# B6x register map
Vendor: XiaoMan; Series: B6 SOC; File version: 20260307
Register cmsis file for DragonC parts
CPU: CM0+ r0p0, little endian, no MPU, no FPU, 2 interrupt priority bits
Registers are 32-bit, read-write, reset 0x0 unless marked. A register's access mark holds for its fields unless they carry their own. Offsets are from the block's base; lines under a group give offsets from that group; [hi:lo] are bit positions; {n}, {i} and the like mark numbered series; 'fields as' and 'values as' point back to an identical list; <NAME> marks a mode.

## Memory map
0x19000000 CACHE size 0x1C
0x40000000 RCC size 0x48 — Reset and Clock Control
0x40001000 SYSCFG size 0x48 — System Configuration
0x40002000 CSC size 0x18C
0x40004000 SPIM size 0x1C — SPI Master
0x40005000 SPIS size 0x14 — SPI Slave
0x40006000 FSHC size 0x60 — Flash Controller
0x40007000 ADC size 0x30
0x40009000 Modem size 0x3C — Modem Freq
0x40010000 GPIO size 0x34
0x40020000 BTMR size 0x5C — basic timer
0x40021000 CTMR size 0x5C — General Purpose Timer
0x40022000 ATMR size 0x5C — Advanced Timer
0x40023000 UART1 size 0x3C
0x40024000 UART2 size 0x3C
0x40026000 DMA size 0xE4C
0x40027000 DMACHCFG size 0x108
0x40028000 EXTI size 0xE30 — External interrupt
0x40029000 I2C size 0x40 — IIC
0x4002A000 IWDT size 0x104 — Independent WatchDog Timer
0x4002C000 RF size 0x78 — Radio Freq
0x40030000 AON size 0x2C — Always On Domain
0x40031000 APBMISC size 0x88

## Interrupts
0 EXTI
1 IWDT
3 DMACHCFG
5 BTMR
6 CTMR
7 ATMR
9 I2C
10 SPIM
11 SPIS
12 UART1_IRQ (UART1)
13 UART2_IRQ (UART2)
14 AON_PMU (AON)
19 FSHC
21 RF

## SYSCFG — System Configuration
Base 0x40001000
0x00 BB_PMU_ENABLE
0x04 AHB_MATRIX_PRIORITY
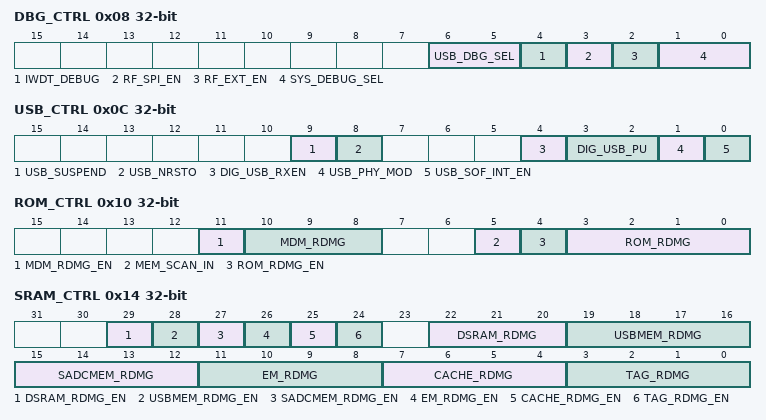
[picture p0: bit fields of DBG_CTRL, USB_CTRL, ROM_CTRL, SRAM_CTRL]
0x08 DBG_CTRL
  [6:5] USB_DBG_SEL
  [4] IWDT_DEBUG
  [3] RF_SPI_EN
    0=Disable (RF reg is direct controlled by APB interface); 1=Enable (RF reg is controlled by SPI interface)
  [2] RF_EXT_EN
    0=Disable (rf reg is controlled by on chip logic); 1=Enable (rf reg is controlled by external through SPI interface)
  [1:0] SYS_DEBUG_SEL
    0=RF Debug Enable (rf_debug port enable); 1=BB Debug Enable (BB debug port enable); 2=Modem Debug Enable (MODEM debug port enable); 3=USB Debug Enable (USB debug port enable)
0x0C USB_CTRL
  [9] USB_SUSPEND
  [8] USB_NRSTO — when is 1, USB is exit reset
  [4] DIG_USB_RXEN
  [3:2] DIG_USB_PU — when is 1, enable pullup 1.5K for DP
  [1] USB_PHY_MOD — when is 1, the chip is set as USB PHY
  [0] USB_SOF_INT_EN — when is 1, USB SOF signal can be used as interrupt
0x10 ROM_CTRL
  [11] MDM_RDMG_EN, [10:8] MDM_RDMG, [5] MEM_SCAN_IN, [4] ROM_RDMG_EN, [3:0] ROM_RDMG
0x14 SRAM_CTRL
  [29] DSRAM_RDMG_EN, [28] USBMEM_RDMG_EN, [27] SADCMEM_RDMG_EN, [26] EM_RDMG_EN, [25] CACHE_RDMG_EN, [24] TAG_RDMG_EN, [22:20] DSRAM_RDMG, [19:16] USBMEM_RDMG, [15:12] SADCMEM_RDMG, [11:8] EM_RDMG, [7:4] CACHE_RDMG, [3:0] TAG_RDMG
0x18 ROM_SIGNATURE_TARGET
0x1C BIST_MODE
0x20 BIST_STATUS
0x24 BIST_STATUS_CLR
0x28 ROM_SIGNATURE_RPT
0x2C CACHSRAM_CFG
0x30 EM_BASE_CFG
0x34 CACHE_ACCESS_CNT
0x38 CACHE_HIT_CNT
0x3C ACC_CCR_BUSY
0x40 MFV_ARRAY_D
0x44 SYS_BACKUP0

## Modem — Modem Freq
Base 0x40009000
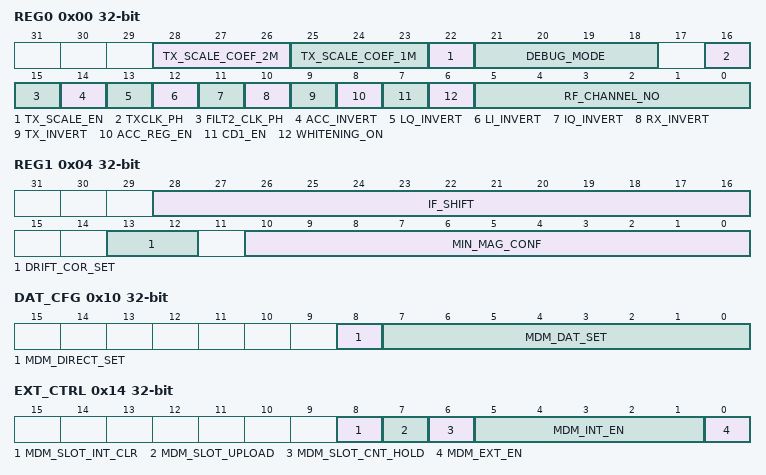
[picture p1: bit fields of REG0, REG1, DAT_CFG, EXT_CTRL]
0x00 REG0
  [28:26] TX_SCALE_COEF_2M — tx_scale_coef[2]==1 : tx_out = tx_in *( 1 + tx_scale_coef[1:0]/16), tx_scale_coef[2]==0 : tx_out = tx_in *( 1 - tx_scale_coef[1:0]/16)
  [25:23] TX_SCALE_COEF_1M — tx_scale_coef[2]==1 : tx_out = tx_in *( 1 + tx_scale_coef[1:0]/16), tx_scale_coef[2]==0 : tx_out = tx_in *( 1 - tx_scale_coef[1:0]/16)
  [22] TX_SCALE_EN — TX_SCALE_EN Enable or Disable
  [21:18] DEBUG_MODE
  [16] TXCLK_PH — TXCLK_PH Enable or Disable
  [15] FILT2_CLK_PH — no use, FILT2_CLK_PH Enable or Disable
  [14] ACC_INVERT — ACC_INVERT Enable or Disable
  [13] LQ_INVERT — LQ_INVERT Enable or Disable
  [12] LI_INVERT — LI_INVERT Enable or Disable
  [11] IQ_INVERT — IQ_INVERT Enable or Disable
  [10] RX_INVERT — RX_INVERT Enable or Disable
  [9] TX_INVERT — TX_INVERT Enable or Disable
  [8] ACC_REG_EN — ACC_REG_EN Enable or Disable
  [7] CD1_EN — CD1_EN Enable or Disable
  [6] WHITENING_ON — WHITENING_ON Enable or Disable
  [5:0] RF_CHANNEL_NO
0x04 REG1
  [28:16] IF_SHIFT, [13:12] DRIFT_COR_SET, [10:0] MIN_MAG_CONF
0x08 CRC_PRESET
0x0C ACCESS_REG
0x10 DAT_CFG
  [8] MDM_DIRECT_SET — 1:modem out data is use mdm_dat_set, 0:modem out use the gauss filter out
  [7:0] MDM_DAT_SET
0x14 EXT_CTRL
  [8] MDM_SLOT_INT_CLR
  [7] MDM_SLOT_UPLOAD
  [6] MDM_SLOT_CNT_HOLD
  [5:1] MDM_INT_EN — 0:mdm_tx_done interrupt en
  [0] MDM_EXT_EN
0x18 RXSYNC_WIN — ( mdm_ext_rxsync_win +1 ) us, max sync time : 4096 us
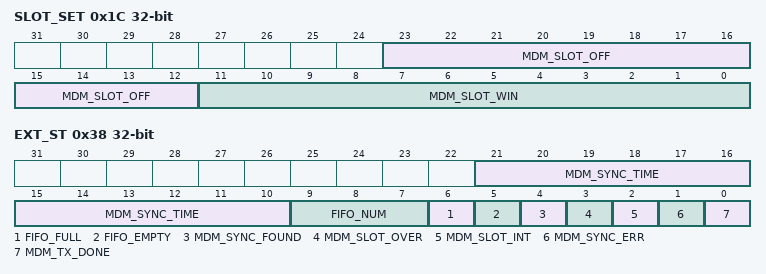
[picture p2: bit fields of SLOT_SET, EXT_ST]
0x1C SLOT_SET
  [23:12] MDM_SLOT_OFF — slot interrput event offset
  [11:0] MDM_SLOT_WIN — slot window : (mdm_slot_win + 1 ) us
0x20 FINECNT_SET
0x24 SLOTCNT_SET
0x28 FINECNT
0x2C SLOTCNT
0x30 EXT_TX_DAT
0x34 EXT_RX_DAT
0x38 EXT_ST
  [21:10] MDM_SYNC_TIME — only valid when mdm_sync_found is 1, cleared when rx_en is 0
  [9:7] FIFO_NUM
  [6] FIFO_FULL
  [5] FIFO_EMPTY
  [4] MDM_SYNC_FOUND — cleared by rx_en is 0
  [3] MDM_SLOT_OVER — cleared by mdm_slot_int_clr
  [2] MDM_SLOT_INT — cleared by mdm_slot_int_clr
  [1] MDM_SYNC_ERR — when RX sync over time, mdm_sync_err is 1, cleared by rx_en is 0
  [0] MDM_TX_DONE — 1:TX fifo is empty and last bit is sent out, cleared when tx_en is 0
